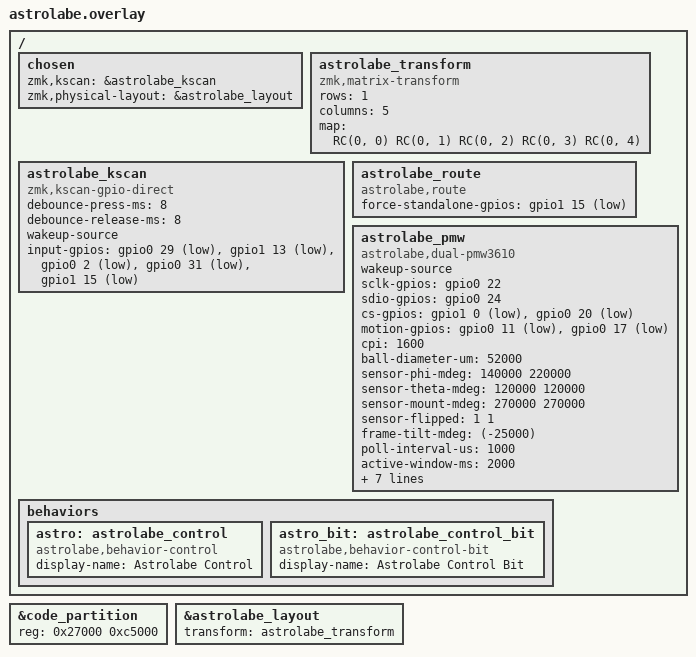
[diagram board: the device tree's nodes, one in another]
// SPDX-FileCopyrightText: 2026 Dylan Lee
// SPDX-License-Identifier: Apache-2.0

#include <dt-bindings/gpio/gpio.h>
#include <dt-bindings/zmk/matrix_transform.h>
#include "astrolabe-layouts.dtsi"

/* The SuperMini is nice!nano v2-compatible in pinout but NOT in flash layout, which is why this
 * shield overrides the board's partition. Its UF2 bootloader bundles SoftDevice S140 7.3.0, one
 * 4 KB page larger than the 6.1.1 a genuine nice!nano v2 ships, so the application starts at
 * 0x27000 rather than upstream's 0x26000. A UF2 built at 0x26000 lands inside the SoftDevice: the
 * bootloader refuses to start it, the board drops straight back to bootloader mode, and it never
 * enumerates -- a total brick-until-reflash, with no partial symptom to notice.
 *
 * This lived in config/boards/supermini_s140_v7.overlay as an opt-in flag. Three separate builds
 * forgot to pass it (CI, the documented command in docs/zmk_migration_plan.md, and a hand build),
 * because nothing fails until the image reaches hardware. It belongs with the rest of the frozen
 * hardware description, where it is applied by construction.
 *
 * Confirmed on hardware: a 0x26000 image failed to enumerate; 0x27000 is correct for this board.
 * If a genuine nice!nano v2 ever needs supporting, it needs its own shield or board target -- do
 * not make this conditional and reintroduce the same footgun.
 */
&code_partition {
    /* 0x27000..0xec000, ending where storage_partition begins, as upstream does. */
    reg = <0x27000 0xc5000>;
};

/ {
    chosen {
        zmk,kscan = &astrolabe_kscan;
        zmk,physical-layout = &astrolabe_layout;
    };

    astrolabe_transform: astrolabe_transform {
        compatible = "zmk,matrix-transform";
        rows = <1>;
        columns = <5>;
        map = <RC(0, 0) RC(0, 1) RC(0, 2) RC(0, 3) RC(0, 4)>;
    };

    astrolabe_kscan: astrolabe_kscan {
        compatible = "zmk,kscan-gpio-direct";
        debounce-press-ms = <8>;
        debounce-release-ms = <8>;
        wakeup-source;
        input-gpios =
            <&gpio0 29 (GPIO_ACTIVE_LOW | GPIO_PULL_UP)>,
            <&gpio1 13 (GPIO_ACTIVE_LOW | GPIO_PULL_UP)>,
            <&gpio0 2  (GPIO_ACTIVE_LOW | GPIO_PULL_UP)>,
            <&gpio0 31 (GPIO_ACTIVE_LOW | GPIO_PULL_UP)>,
            <&gpio1 15 (GPIO_ACTIVE_LOW | GPIO_PULL_UP)>;
    };

    astrolabe_route: astrolabe_route {
        compatible = "astrolabe,route";
        // Intentionally the same pin as kscan input 4 (Center): holding Center through boot is the
        // forced-standalone escape. Both drivers configure this pin, and that is safe only because
        // the one-shot route probe runs at POST_KERNEL/40 while kscan runs at POST_KERNEL/90, so
        // kscan configures it last and owns the interrupt. Keep that ordering if either moves.
        force-standalone-gpios = <&gpio1 15 (GPIO_ACTIVE_LOW | GPIO_PULL_UP)>;
    };

    astrolabe_pmw: astrolabe_pmw {
        compatible = "astrolabe,dual-pmw3610";
        status = "okay";
        wakeup-source;

        sclk-gpios = <&gpio0 22 GPIO_ACTIVE_HIGH>;
        sdio-gpios = <&gpio0 24 GPIO_ACTIVE_HIGH>;
        cs-gpios = <&gpio1 0 GPIO_ACTIVE_LOW>, <&gpio0 20 GPIO_ACTIVE_LOW>;
        motion-gpios = <&gpio0 11 (GPIO_ACTIVE_LOW | GPIO_PULL_UP)>,
                       <&gpio0 17 (GPIO_ACTIVE_LOW | GPIO_PULL_UP)>;

        cpi = <1600>;
        ball-diameter-um = <52000>;
        sensor-phi-mdeg = <140000 220000>;
        sensor-theta-mdeg = <120000 120000>;
        sensor-mount-mdeg = <270000 270000>;
        sensor-flipped = <1 1>;
        frame-tilt-mdeg = <(-25000)>;

        poll-interval-us = <1000>;
        active-window-ms = <2000>;
        send-interval-ms = <7>;
        /* Per radian of ball rotation, not per sensor count: independent of ball-diameter-um and
         * cpi, and the same units the daemon's profile uses so standalone and daemon output can be
         * compared directly. yaw-deadzone is the daemon's tuned 0.004 rad -- it was previously
         * 1.2, which reads as 1.2 counts (0.00075 rad), five times more permissive than the
         * reference, so noise-level yaw cleared it and scroll-hold-ms latched the false positive. */
        cursor-gain-milli = <200000>;
        scroll-gain-milli = <400000>;
        scroll-divisor = <60>;
        yaw-deadzone-milli = <4>;
        yaw-dominance-milli = <1700>;
        scroll-hold-ms = <80>;
    };

    behaviors {
        astro: astrolabe_control {
            compatible = "astrolabe,behavior-control";
            #binding-cells = <2>;
            display-name = "Astrolabe Control";
        };

        /* One parameter, so it can sit inside a hold-tap, which passes only one. Reports no
         * standalone mouse button, so it suits Up and Left and nothing else. */
        astro_bit: astrolabe_control_bit {
            compatible = "astrolabe,behavior-control-bit";
            #binding-cells = <1>;
            display-name = "Astrolabe Control Bit";
        };
    };

};

&astrolabe_layout {
    transform = <&astrolabe_transform>;
};
